AUTOSAR XML (schema 4-3-0)
standard types defined: uint8, uint8_DataConstr
package /ComponentTypes/HkmcVehicleOutputSWC
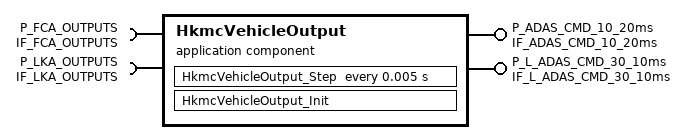
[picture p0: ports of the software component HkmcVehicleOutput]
  application sw component type HkmcVehicleOutput
    provide port P_ADAS_CMD_10_20ms: nonqueued-sender-com-spec{data-element=DE_ADAS_CMD_10_20ms, init-value=constant-reference=CS_VehicleOutput_ADAS_CMD_10_20ms}, provided-interface=IF_ADAS_CMD_10_20ms
    provide port P_L_ADAS_CMD_30_10ms: nonqueued-sender-com-spec{data-element=DE_L_ADAS_CMD_30_10ms, init-value=constant-reference=CS_VehicleOutput_L_ADAS_CMD_30_10ms}, provided-interface=IF_L_ADAS_CMD_30_10ms
    require port P_FCA_OUTPUTS: nonqueued-receiver-com-spec{data-element=DE_FCA_OUTPUTS, filter=data-filter-type=ALWAYS, init-value=constant-reference=CS_VehicleOutput_FCA_Output}, required-interface=IF_FCA_OUTPUTS
    require port P_LKA_OUTPUTS: nonqueued-receiver-com-spec{data-element=DE_LKA_OUTPUTS, filter=data-filter-type=ALWAYS, init-value=constant-reference=CS_VehicleOutput_LKA_OUTPUT}, required-interface=IF_LKA_OUTPUTS
    behavior HkmcVehicleOutput_InternalBehavior
      init event HkmcVehicleOutput_InitEvent: start-on-event=HkmcVehicleOutput_Init
      timing event HkmcVehicleOutput_Step_TE: start-on-event=HkmcVehicleOutput_Step, period=0.005
      runnable HkmcVehicleOutput_Init
        data-receive-point-by-arguments:
          access REC_P_FCA_OUTPUTS_DE_FCA_OUTPUTS: accessed-variable=P_FCA_OUTPUTS.DE_FCA_OUTPUTS
          access REC_P_LKA_OUTPUTS_DE_LKA_OUTPUTS: accessed-variable=P_LKA_OUTPUTS.DE_LKA_OUTPUTS
        data-send-points:
          access SEND_P_ADAS_CMD_10_20ms_DE_ADAS_CMD_10_20ms: accessed-variable=P_ADAS_CMD_10_20ms.DE_ADAS_CMD_10_20ms
          access SEND_P_L_ADAS_CMD_30_10ms_DE_L_ADAS_CMD_30_10ms: accessed-variable=P_L_ADAS_CMD_30_10ms.DE_L_ADAS_CMD_30_10ms
      runnable HkmcVehicleOutput_Step
        data-receive-point-by-arguments:
          access REC_P_FCA_OUTPUTS_DE_FCA_OUTPUTS: accessed-variable=P_FCA_OUTPUTS.DE_FCA_OUTPUTS
          access REC_P_LKA_OUTPUTS_DE_LKA_OUTPUTS: accessed-variable=P_LKA_OUTPUTS.DE_LKA_OUTPUTS
        data-send-points:
          access SEND_P_ADAS_CMD_10_20ms_DE_ADAS_CMD_10_20ms: accessed-variable=P_ADAS_CMD_10_20ms.DE_ADAS_CMD_10_20ms
          access SEND_P_L_ADAS_CMD_30_10ms_DE_L_ADAS_CMD_30_10ms: accessed-variable=P_L_ADAS_CMD_30_10ms.DE_L_ADAS_CMD_30_10ms
  swc implementation HkmcVehicleOutput_Implementation: behavior=HkmcVehicleOutput_InternalBehavior
    code-descriptors:
      code Default: artifact-descriptors=autosar-engineering-object={short-label=Default, category=SWSRC}
package /ComponentTypes/HkmcVehicleOutputSWC/Constants
  4 x constant specification:
    CS_VehicleOutput_ADAS_CMD_10_20ms: value-spec=fields=[FCA_WrngLvlSta:0, FCA_VehStpReq:0, FCA_StbltActvReq:0, FCA_DclReqVal:0, FCA_PrefillActvReq:0, FCA_FullActvReq:0, FCA_TimetoCllsn:0, FCA_WrngTrgtDis:0, FCA_PartialActvReq:0]
    CS_VehicleOutput_FCA_Output: value-spec=fields=[FCA_WrngLvlSta:0, FCA_VehStpReq:0, FCA_StbltActvReq:0, FCA_DclReqVal:0, FCA_PrefillActvReq:0, FCA_FullActvReq:0, FCA_TimetoCllsn:0, FCA_WrngTrgtDis:0, FCA_PartialActvReq:0]
    CS_VehicleOutput_L_ADAS_CMD_30_10ms: value-spec=fields=[LKA_OptUsmSta_Copy_1:0, LKA_LHLnWrnSta_Copy_1:0, LKA_RHLnWrnSta_Copy_1:0]
    CS_VehicleOutput_LKA_OUTPUT: value-spec=fields=[LKA_OptUsmSta_Copy_1:0, LKA_LHLnWrnSta_Copy_1:0, LKA_RHLnWrnSta_Copy_1:0]
package /ComponentTypes/HkmcVehicleOutputSWC/DataTypes
  4 x impl type, all with category=STRUCTURE, type-emitter=RTE:
    ADAS_CMD_10_20ms
      9 x element, all with category=TYPE_REFERENCE, implementation-data-type=uint8:
        FCA_WrngLvlSta
        FCA_VehStpReq
        FCA_StbltActvReq
        FCA_DclReqVal
        FCA_PrefillActvReq
        FCA_FullActvReq
        FCA_TimetoCllsn
        FCA_WrngTrgtDis
        FCA_PartialActvReq
    FCA_OUTPUTS_T
      9 x element, all with category=TYPE_REFERENCE, implementation-data-type=uint8:
        FCA_WrngLvlSta
        FCA_VehStpReq
        FCA_StbltActvReq
        FCA_DclReqVal
        FCA_PrefillActvReq
        FCA_FullActvReq
        FCA_TimetoCllsn
        FCA_WrngTrgtDis
        FCA_PartialActvReq
    L_ADAS_CMD_30_10ms
      element LKA_OptUsmSta_Copy_1: implementation-data-type=uint8
      element LKA_LHLnWrnSta_Copy_1: implementation-data-type=uint8
      element LKA_RHLnWrnSta_Copy_1: implementation-data-type=uint8
    LKA_OUTPUTS_T
      element LKA_OptUsmSta_Copy_1: implementation-data-type=uint8
      element LKA_LHLnWrnSta_Copy_1: implementation-data-type=uint8
      element LKA_RHLnWrnSta_Copy_1: implementation-data-type=uint8
package /ComponentTypes/HkmcVehicleOutputSWC/PortInterfaces
  4 x sender receiver interface:
    IF_ADAS_CMD_10_20ms: invalidation-policy{data-element=DE_ADAS_CMD_10_20ms, handle-invalid=DONT-INVALIDATE}
      data DE_ADAS_CMD_10_20ms: type=ADAS_CMD_10_20ms
    IF_FCA_OUTPUTS: invalidation-policy{data-element=DE_FCA_OUTPUTS, handle-invalid=DONT-INVALIDATE}
      data DE_FCA_OUTPUTS: type=FCA_OUTPUTS_T
    IF_L_ADAS_CMD_30_10ms: invalidation-policy{data-element=DE_L_ADAS_CMD_30_10ms, handle-invalid=DONT-INVALIDATE}
      data DE_L_ADAS_CMD_30_10ms: type=L_ADAS_CMD_30_10ms
    IF_LKA_OUTPUTS: invalidation-policy{data-element=DE_LKA_OUTPUTS, handle-invalid=DONT-INVALIDATE}
      data DE_LKA_OUTPUTS: type=LKA_OUTPUTS_T
